# MIK32 register map
Vendor: Mikron JSC; Series: MIK32; File version: 1.0
Registers are 32-bit, read-write, reset 0x0 unless marked. A register's access mark holds for its fields unless they carry their own. Offsets are from the block's base; [hi:lo] are bit positions.

## TIMER32_0 — Регистры модуля TIMER32_0
Base 0x00050800
0x00 VALUE ro — Текущее значение основного таймера
  [31:0] TIM_VAL — Текущее значение счётчика
0x04 TOP reset 0xFFFFFFFF — максимальное значение счётной последовательности
  [31:0] TIM_TOP — максимальное значение счётчика (ограничивает счётную последоваельность сверху)
0x08 PRESCALE — значение делителя
  [31:0] TIM_PRESCALE — Значение предварительного делителя. Предделитель вырабатывает тактовый сигнал для счёта, частота которого в целое раз меньше входной
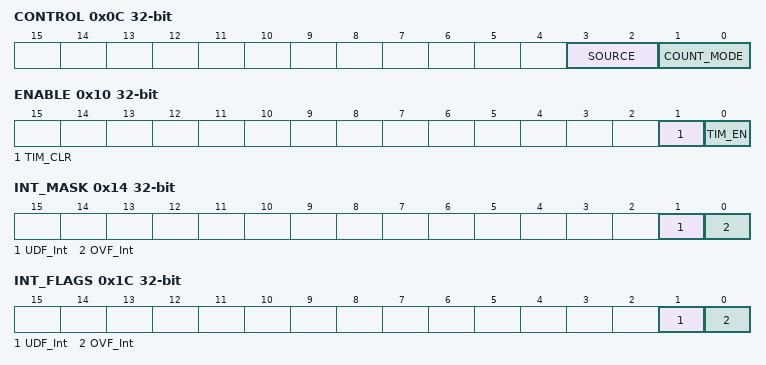
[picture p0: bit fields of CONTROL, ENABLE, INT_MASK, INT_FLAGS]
0x0C CONTROL reset not defined — Конфигурационный регистр основного таймера
  [3:2] SOURCE — Выбор источника тактового сигнала для счёта
    0=APB_M (частота APB_M); 1=TIM1 (синхронный вход тактирования TIM1); 2=TIMER32_0_Tx (вход TIMER32_0_Tx микросхемы); 3=TIM2 (асинхронный вход тактирования TIM2)
  [1:0] COUNT_MODE — Режим счёта таймера
    0=Direct (Прямой режим); 1=Reverse (Обратный режим); 2=Bidirectional (Двунаправленный режим)
0x10 ENABLE — Регистр включения таймера
  [1] TIM_CLR write-once — Сброс (обнуление) текущего значения счётчика при записи «1»
  [0] TIM_EN — Запуск/остановка работы счётчика
    0=Disable (Счётчик выключен); 1=Enable (Счётчик работает)
0x14 INT_MASK — Регистр маски прерываний
  [1] UDF_Int — Маска прерывания опустошения счётчика
  [0] OVF_Int — Маска прерывания по переполнению счётчика
0x18 INT_CLEAR reset 0xFFFFFFFF — Регистр сброса флагов прерываний
0x1C INT_FLAGS ro — Регистр флагов прерываний
  [1] UDF_Int — Статус прерывания опустошения счётчика
  [0] OVF_Int — Статус прерывания по переполнению счётчика

## GPIO_0 — Модуль ввода/вывода
Base 0x00084000
Same registers: GPIO_1 0x00084400
0x00 SET — Текущее состояние выводов (STATE) / Установка в «1» (SET) При чтении – текущее состояние выводов. При записи «1» соответствующий биту вывод устанавливается в «1»
0x04 CLEAR — Текущее состояние запросов прерываний (IRQ_STATE) / Установка в «0» (CLEAR) При чтении – текущее состояние запросов прерываний. При записи «1» соответствующий биту вывод устанавливается в «0»
0x08 DIRECTION_OUT reset 0xFFFF — Установка направления выводов как выход При чтении – текущее направление выводов: 0 – выход; 1 – вход. Запись «1» устанавливает соответствующий вывод как «выход»
0x0C DIRECTION_IN reset 0xFFFF — Установка направления выводов как вход При чтении – текущее направление выводов: 0 – выход; 1 – вход. Запись «1» устанавливает соответствующий вывод как «вход»
0x10 OUTPUT — Выходной регистр Чтение возвращает содержимое выходного регистра независимо от текущего направления выводов Запись устанавливает значения всех битов выходного регистра
0x14 CONTROL — Тестовый режим Запись «1» в [0:0] разряд – включение тестового режима (выходы замкнуты на входы внутри модуля) Запись «0» в [0:0] разряд – нормальный режим

## GPIO_2 — Модуль ввода/вывода
Base 0x00084800
Registers as GPIO_0; these are added or differ:
0x08 DIRECTION_OUT reset 0xFF — Установка направления выводов как выход При чтении – текущее направление выводов: 0 – выход; 1 – вход. Запись «1» устанавливает соответствующий вывод как «выход»
0x0C DIRECTION_IN reset 0xFF — Установка направления выводов как вход При чтении – текущее направление выводов: 0 – выход; 1 – вход. Запись «1» устанавливает соответствующий вывод как «вход»

## GPIO_IRQ — Модуль формирования прерываний
Base 0x00084C00
0x00 STATE ro — Текущее состояние выводов линий после мультисплексоров. Номер бита соответсвует номеру канала.
0x04 LINE_MUX — Управление мультиплексорами. Каждый мультиплесор управляется своими 4 битами: Mux_0 – [3:0]; Mux_1 – [7:4]; Mux_2 – [11:8]; Mux_3 – [15:12]; Mux_4 – [19:16]; Mux_5– [23:20]; Mux_6 – [27:24]; Mux_7 – [31:28]
0x08 INTERRUPT — Текущее состояние прерываний. Номер бита соответсвует номеру канала.
0x0C ENABLE_SET — Регистр разрешения прерываний При чтении – текущее состояние разрешений прерываний. При записи «1» разрешает прерывание от соответствующего канала.
0x10 ENABLE_CLEAR — Регистр запрета прерываний При чтении – текущее состояние разрешений прерываний. При записи «1» запрещает прерывание от соответствующего канала
0x14 EDGE — Регистр типа прерываний. При чтении – текущий тип прерывания: «1» – по событию (фронт или спад), «0» – по уровню. Запись «1» – прерывание формируется по событию для соответствующего канала Запись «0» - не влияет
0x18 LEVEL reset 0xFF — Регистр типа прерываний. При чтении – текущий тип прерывания (инвертированный): «0» – по событию; «1» – по уровню. Запись «1» – прерывание формируется по уровню для соответствующего канала Запись «0» - не влияет
0x1C LEVEL_SET — Регистр выбора уровня / события прерываний. При чтении: «0» – прерывания формируются по спаду или уровню логического «0»; «1» – прерывания формируются по нарастающему фронту или уровню логической «1» Запись «1» – прерывание формируется по нарастающему фронту или уровню логической «1» для соответствующего канала
0x20 LEVEL_CLEAR — Регистр уровня / со-бытия прерываний. При чтении: «0» – прерывания формируются по спаду или уровню логического «0»; «1» – прерывания формируются по нарастающему фронту или уровню логической «1» Запись «1»– прерывание формируется по спаду или уровню логического «0» для соответствующего канала
0x24 ANY_EDGE_SET — Регистр прерываний по любому событию. Запись «1» – прерывание формируется по любому изменению соответствующего канала
0x28 ANY_EDGE_CLEAR — Регистр прерываний по любому событию. Запись «1» – прерывание не формируется по любому изменению соответствующего канала
0x2C CLEAR wo write-1-clears — Регистр сброса флагов прерываний по событию. Запись «1» – очищает флаг прерывания соответствующего канала
